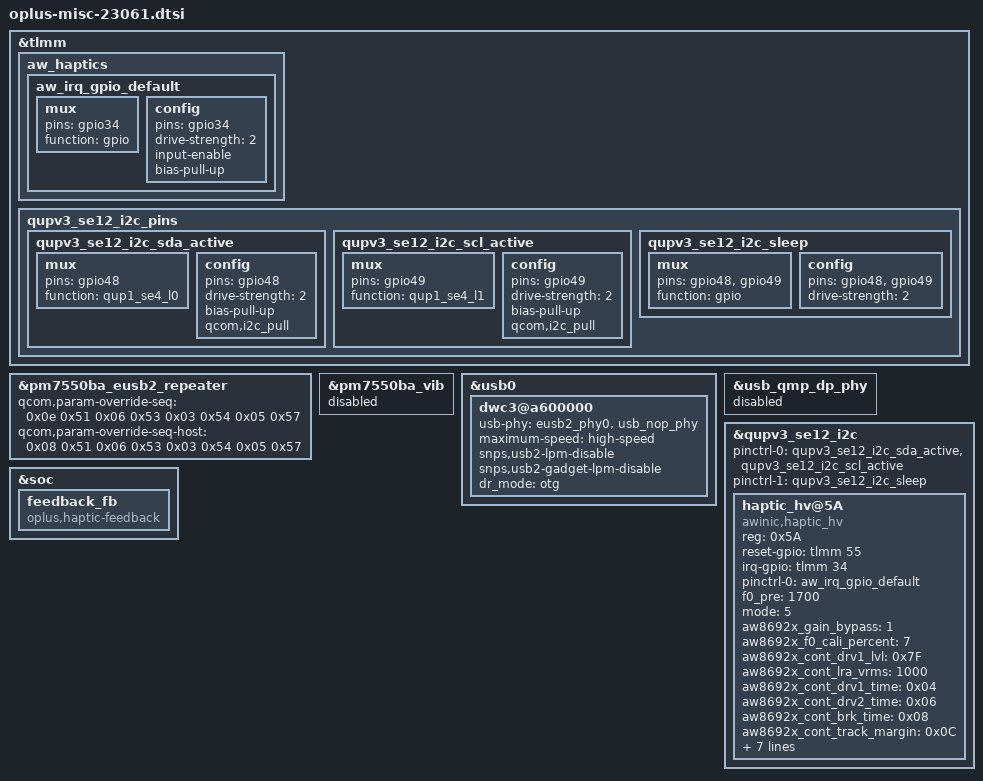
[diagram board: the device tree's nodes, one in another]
&tlmm {
	aw_haptics: aw_haptics {
		aw_irq_gpio_default: aw_irq_gpio_default {
			mux {
				pins = "gpio34";
				function = "gpio";
			};

			config {
				pins = "gpio34";
				drive-strength = <2>;
				input-enable;
				bias-pull-up;
			};
		};
	};

	qupv3_se12_i2c_pins: qupv3_se12_i2c_pins {
		qupv3_se12_i2c_sda_active: qupv3_se12_i2c_sda_active {
			mux {
				pins = "gpio48";
				function = "qup1_se4_l0";
			};

			config {
				pins = "gpio48";
				drive-strength = <2>;
				bias-pull-up;
				qcom,i2c_pull;
			};
		};

		qupv3_se12_i2c_scl_active: qupv3_se12_i2c_scl_active {
			mux {
				pins = "gpio49";
				function = "qup1_se4_l1";
			};

			config {
				pins = "gpio49";
				drive-strength = <2>;
				bias-pull-up;
				qcom,i2c_pull;
			};
		};

		qupv3_se12_i2c_sleep: qupv3_se12_i2c_sleep {
			mux {
				pins = "gpio48", "gpio49";
				function = "gpio";
			};

			config {
				pins = "gpio48", "gpio49";
				drive-strength = <2>;
			};
		};
	};
};

&pm7550ba_eusb2_repeater {
	qcom,param-override-seq = <0x0e 0x51 0x06 0x53 0x03 0x54 0x05 0x57>;
	qcom,param-override-seq-host = <0x08 0x51 0x06 0x53 0x03 0x54 0x05 0x57>;
};

&pm7550ba_vib {
	status = "disabled";
};

&usb0 {
/delete-property/ extcon;
	dwc3@a600000 {
		usb-phy = <&eusb2_phy0>, <&usb_nop_phy>;
		maximum-speed = "high-speed";
		snps,usb2-lpm-disable;
		snps,usb2-gadget-lpm-disable;
		dr_mode = "otg";
	};
};

&usb_qmp_dp_phy {
	status = "disabled";
};

&qupv3_se12_i2c {
	pinctrl-names = "default", "sleep";
	pinctrl-0 = <&qupv3_se12_i2c_sda_active>, <&qupv3_se12_i2c_scl_active>;
	pinctrl-1 = <&qupv3_se12_i2c_sleep>;
	status = "ok";
	/* AWINIC AW86927 Haptic, motor values as stock (device id 809) */
	haptic_hv@5A {
		compatible = "awinic,haptic_hv";
		reg = <0x5A>;
		reset-gpio = <&tlmm 55 0>;
		irq-gpio = <&tlmm 34 0>;
		status = "ok";
		pinctrl-names = "default";
		pinctrl-0 = <&aw_irq_gpio_default>;
		f0_pre = <1700>;
		mode = /bits/ 8 <5>;

		aw8692x_gain_bypass = /bits/ 8 <1>;
		aw8692x_f0_cali_percent = /bits/ 8 <7>;
		aw8692x_cont_drv1_lvl = /bits/ 8 <0x7F>;
		aw8692x_cont_lra_vrms = <1000>;
		aw8692x_cont_drv1_time = /bits/ 8 <0x04>;
		aw8692x_cont_drv2_time = /bits/ 8 <0x06>;
		aw8692x_cont_brk_time = /bits/ 8 <0x08>;
		aw8692x_cont_track_margin = /bits/ 8 <0x0C>;
		aw8692x_cont_brk_gain = /bits/ 8 <0x06>;
		aw8692x_d2s_gain = /bits/ 8 <0x05>;
		aw8692x_duration_time = /bits/ 8 <20 30 60>;
		aw8692x_trig_config = /bits/ 8 <0 0 0 1 0 2 0 0
						0 0 0 1 0 2 0 0
						0 0 0 1 0 2 0 0>;
		/* Boost register 0x55 */
		aw8692x_bst_vol_default = <8813>;
		aw8692x_is_enabled_track_en;
	};
	/* AWINIC AW86927 Haptic End */
};

&soc {
	feedback_fb: feedback_fb {
		compatible = "oplus,haptic-feedback";
	};
};
